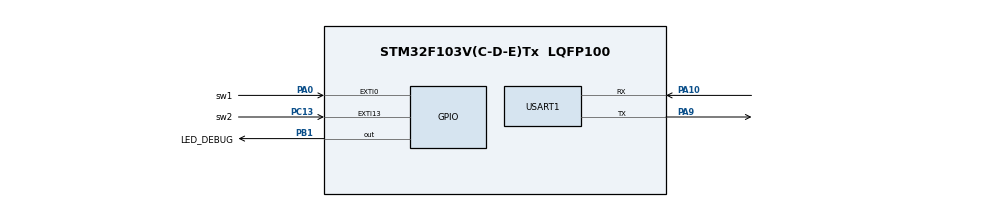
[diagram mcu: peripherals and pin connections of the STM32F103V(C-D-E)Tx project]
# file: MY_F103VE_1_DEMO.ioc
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Mcu.Family=STM32F1
Mcu.Name=STM32F103V(C-D-E)Tx
Mcu.Package=LQFP100
NVIC.EXTI0_IRQn=true\:0\:0\:false\:false\:true\:true\:true\:true
NVIC.EXTI15_10_IRQn=true\:0\:0\:false\:false\:true\:true\:true\:true
NVIC.PriorityGroup=NVIC_PRIORITYGROUP_4
NVIC.USART1_IRQn=true\:0\:0\:false\:false\:true\:true\:true\:true
PA0-WKUP.GPIO_Label=sw1
PA0-WKUP.GPIO_ModeDefaultEXTI=GPIO_MODE_IT_RISING_FALLING
PA0-WKUP.GPIO_PuPd=GPIO_PULLUP
PA0-WKUP.Signal=GPXTI0
PA10.Mode=Asynchronous
PA10.Signal=USART1_RX
PA9.Mode=Asynchronous
PA9.Signal=USART1_TX
PB1.GPIO_Label=LED_DEBUG
PB1.PinState=GPIO_PIN_SET
PB1.Signal=GPIO_Output
PC13-TAMPER-RTC.GPIO_Label=sw2
PC13-TAMPER-RTC.GPIO_ModeDefaultEXTI=GPIO_MODE_IT_RISING_FALLING
PC13-TAMPER-RTC.GPIO_PuPd=GPIO_PULLUP
PC13-TAMPER-RTC.Signal=GPXTI13
ProjectManager.HeapSize=0x200
ProjectManager.StackSize=0x400
ProjectManager.TargetToolchain=MDK-ARM V5.32
RCC.APB1Freq_Value=8000000
RCC.APB2Freq_Value=8000000
USART1.VirtualMode=VM_ASYNC
VP_SYS_VS_ND.Mode=No_Debug
board=custom

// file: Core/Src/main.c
/* USER CODE BEGIN Header */
/**
  ******************************************************************************
  * @file           : main.c
  * @brief          : Main program body
  ******************************************************************************
  * @attention
  *
  * Copyright (c) 2024 STMicroelectronics.
  * All rights reserved.
  *
  * This software is licensed under terms that can be found in the LICENSE file
  * in the root directory of this software component.
  * If no LICENSE file comes with this software, it is provided AS-IS.
  *
  ******************************************************************************
  */
/* USER CODE END Header */
#include "main.h"

/* USER CODE BEGIN Includes */
#include "ws_drive_borad.h"
/* USER CODE END Includes */

UART_HandleTypeDef huart1;

void SystemClock_Config(void);
static void MX_GPIO_Init(void);
static void MX_USART1_UART_Init(void);

int main(void)
{

  /* USER CODE BEGIN 1 */
	int count=0;
	uint8_t key = 0;
  /* USER CODE END 1 */

  /* MCU Configuration--------------------------------------------------------*/

  /* Reset of all peripherals, Initializes the Flash interface and the Systick. */
  HAL_Init();

  /* Configure the system clock */
  SystemClock_Config();

  /* Initialize all configured peripherals */
  MX_GPIO_Init();
  MX_USART1_UART_Init();

  /* Infinite loop */
  /* USER CODE BEGIN WHILE */
  while (1)
  {
	  if(++ count == 50)
	  {
		  count = 0;
		   HAL_GPIO_TogglePin(LED_DEBUG_GPIO_Port,LED_DEBUG_Pin);
	  }
// 使用(uint8_t) 就是取GPIOX->IDR的低8位
//  0xfffe ---> 0x1111 1111 1111 1101 为1 的地方是屏蔽 为 0的地方保留下来读取
	 key = GetKeyDFallingEdge((uint8_t)(GPIOA->IDR | 0xfffe)); // sw1

	  if(key > 0)
	  {
		  WS_Debug("Key:%d\r\n",key);
	  }

	  HAL_Delay(10);

    /* USER CODE END WHILE */

  }
}

void SystemClock_Config(void)
{
  RCC_OscInitTypeDef RCC_OscInitStruct = {0};
  RCC_ClkInitTypeDef RCC_ClkInitStruct = {0};

  /** Initializes the RCC Oscillators according to the specified parameters
  * in the RCC_OscInitTypeDef structure.
  */
  RCC_OscInitStruct.OscillatorType = RCC_OSCILLATORTYPE_HSI;
  RCC_OscInitStruct.HSIState = RCC_HSI_ON;
  RCC_OscInitStruct.HSICalibrationValue = RCC_HSICALIBRATION_DEFAULT;
  RCC_OscInitStruct.PLL.PLLState = RCC_PLL_NONE;
  if (HAL_RCC_OscConfig(&RCC_OscInitStruct) != HAL_OK)
  {
    Error_Handler();
  }

  /** Initializes the CPU, AHB and APB buses clocks
  */
  RCC_ClkInitStruct.ClockType = RCC_CLOCKTYPE_HCLK|RCC_CLOCKTYPE_SYSCLK
                              |RCC_CLOCKTYPE_PCLK1|RCC_CLOCKTYPE_PCLK2;
  RCC_ClkInitStruct.SYSCLKSource = RCC_SYSCLKSOURCE_HSI;
  RCC_ClkInitStruct.AHBCLKDivider = RCC_SYSCLK_DIV1;
  RCC_ClkInitStruct.APB1CLKDivider = RCC_HCLK_DIV1;
  RCC_ClkInitStruct.APB2CLKDivider = RCC_HCLK_DIV1;

  if (HAL_RCC_ClockConfig(&RCC_ClkInitStruct, FLASH_LATENCY_0) != HAL_OK)
  {
    Error_Handler();
  }
}

static void MX_USART1_UART_Init(void)
{

  huart1.Instance = USART1;
  huart1.Init.BaudRate = 115200;
  huart1.Init.WordLength = UART_WORDLENGTH_8B;
  huart1.Init.StopBits = UART_STOPBITS_1;
  huart1.Init.Parity = UART_PARITY_NONE;
  huart1.Init.Mode = UART_MODE_TX_RX;
  huart1.Init.HwFlowCtl = UART_HWCONTROL_NONE;
  huart1.Init.OverSampling = UART_OVERSAMPLING_16;
  if (HAL_UART_Init(&huart1) != HAL_OK)
  {
    Error_Handler();
  }

}

static void MX_GPIO_Init(void)
{
  GPIO_InitTypeDef GPIO_InitStruct = {0};

  /* GPIO Ports Clock Enable */
  __HAL_RCC_GPIOC_CLK_ENABLE();
  __HAL_RCC_GPIOA_CLK_ENABLE();
  __HAL_RCC_GPIOB_CLK_ENABLE();

  /*Configure GPIO pin Output Level */
  HAL_GPIO_WritePin(LED_DEBUG_GPIO_Port, LED_DEBUG_Pin, GPIO_PIN_SET);

  /*Configure GPIO pin : sw2_Pin */
  GPIO_InitStruct.Pin = sw2_Pin;
  GPIO_InitStruct.Mode = GPIO_MODE_IT_RISING_FALLING;
  GPIO_InitStruct.Pull = GPIO_PULLUP;
  HAL_GPIO_Init(sw2_GPIO_Port, &GPIO_InitStruct);

  /*Configure GPIO pin : sw1_Pin */
  GPIO_InitStruct.Pin = sw1_Pin;
  GPIO_InitStruct.Mode = GPIO_MODE_IT_RISING_FALLING;
  GPIO_InitStruct.Pull = GPIO_PULLUP;
  HAL_GPIO_Init(sw1_GPIO_Port, &GPIO_InitStruct);

  /*Configure GPIO pin : LED_DEBUG_Pin */
  GPIO_InitStruct.Pin = LED_DEBUG_Pin;
  GPIO_InitStruct.Mode = GPIO_MODE_OUTPUT_PP;
  GPIO_InitStruct.Pull = GPIO_NOPULL;
  GPIO_InitStruct.Speed = GPIO_SPEED_FREQ_LOW;
  HAL_GPIO_Init(LED_DEBUG_GPIO_Port, &GPIO_InitStruct);

  /* EXTI interrupt init*/
  HAL_NVIC_SetPriority(EXTI0_IRQn, 0, 0);
  HAL_NVIC_EnableIRQ(EXTI0_IRQn);

  HAL_NVIC_SetPriority(EXTI15_10_IRQn, 0, 0);
  HAL_NVIC_EnableIRQ(EXTI15_10_IRQn);

}

void Error_Handler(void)
{
  __disable_irq();
  while (1)
  {
  }
}
